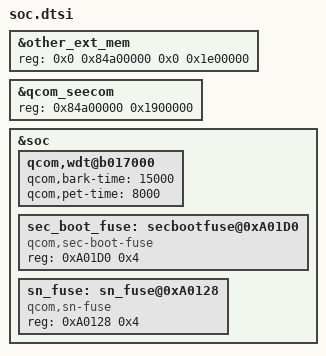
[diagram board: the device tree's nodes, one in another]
&other_ext_mem {
	reg = <0x0 0x84a00000 0x0 0x1e00000>;
};

&qcom_seecom {
	reg = <0x84a00000 0x1900000>;
};

&soc {
	qcom,wdt@b017000 {
		qcom,bark-time = <15000>;
		qcom,pet-time = <8000>;
	};

	sec_boot_fuse: secbootfuse@0xA01D0 {
		compatible = "qcom,sec-boot-fuse";
		reg = <0xA01D0 0x4>;
		reg-names = "sec-boot-base";
	};

	sn_fuse: sn_fuse@0xA0128 {
		compatible = "qcom,sn-fuse";
		reg = <0xA0128 0x4>;
		reg-names = "sn-base";
	};
};
